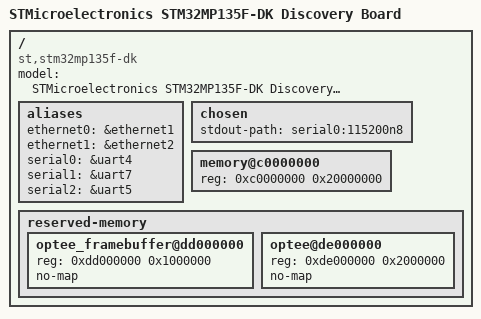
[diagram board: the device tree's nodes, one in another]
// SPDX-License-Identifier: (GPL-2.0+ OR BSD-3-Clause)
/*
 * Copyright (C) MYiR 2022 - All Rights Reserved
 * Author: Alexhu <fan.hu@myirtech.com> for MYiR.
 */

/dts-v1/;

#include "myb-stm32mp135x-base.dtsi"

/ {
	model = "STMicroelectronics STM32MP135F-DK Discovery Board";
	compatible = "st,stm32mp135f-dk", "st,stm32mp135";

	aliases {
		ethernet0 = &ethernet1;
		ethernet1 = &ethernet2;
		serial0 = &uart4;
		serial1 = &uart7;
		serial2 = &uart5;
	};

	chosen {
		#address-cells = <1>;
		#size-cells = <1>;
		ranges;
		stdout-path = "serial0:115200n8";
	};

	memory@c0000000 {
		device_type = "memory";
		reg = <0xc0000000 0x20000000>;
	};

	reserved-memory {
		#address-cells = <1>;
		#size-cells = <1>;
		ranges;

		optee_framebuffer@dd000000 {
			reg = <0xdd000000 0x1000000>;
			no-map;
		};

		optee@de000000 {
			reg = <0xde000000 0x2000000>;
			no-map;
		};
	};

};
